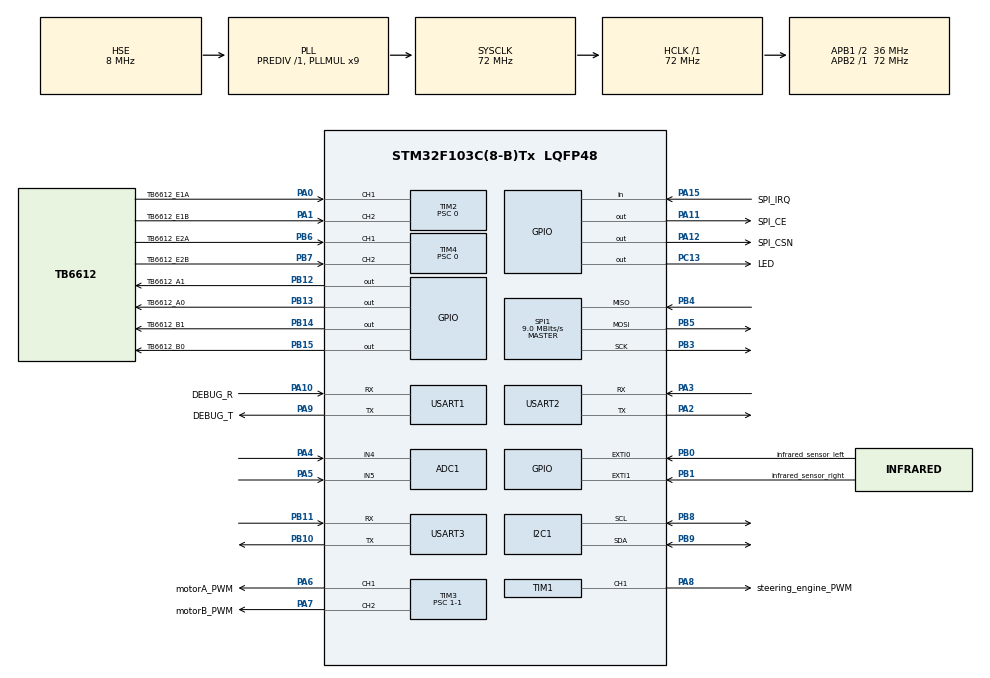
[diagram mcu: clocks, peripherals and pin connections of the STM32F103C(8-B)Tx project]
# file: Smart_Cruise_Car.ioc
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ADC1.Channel-0\#ChannelRegularConversion=ADC_CHANNEL_4
ADC1.NbrOfConversionFlag=1
ADC1.Rank-0\#ChannelRegularConversion=1
ADC1.SamplingTime-0\#ChannelRegularConversion=ADC_SAMPLETIME_1CYCLE_5
ADC1.master=1
Dma.Request0=USART1_RX
Dma.Request1=USART1_TX
Dma.Request2=USART2_RX
Dma.Request3=USART2_TX
Dma.Request4=USART3_RX
Dma.Request5=USART3_TX
Dma.USART1_RX.0.Direction=DMA_PERIPH_TO_MEMORY
Dma.USART1_RX.0.Instance=DMA1_Channel5
Dma.USART1_RX.0.MemDataAlignment=DMA_MDATAALIGN_BYTE
Dma.USART1_RX.0.MemInc=DMA_MINC_ENABLE
Dma.USART1_RX.0.Mode=DMA_NORMAL
Dma.USART1_RX.0.PeriphDataAlignment=DMA_PDATAALIGN_BYTE
Dma.USART1_RX.0.PeriphInc=DMA_PINC_DISABLE
Dma.USART1_RX.0.Priority=DMA_PRIORITY_LOW
Dma.USART1_TX.1.Direction=DMA_MEMORY_TO_PERIPH
Dma.USART1_TX.1.Instance=DMA1_Channel4
Dma.USART1_TX.1.MemDataAlignment=DMA_MDATAALIGN_BYTE
Dma.USART1_TX.1.MemInc=DMA_MINC_ENABLE
Dma.USART1_TX.1.Mode=DMA_NORMAL
Dma.USART1_TX.1.PeriphDataAlignment=DMA_PDATAALIGN_BYTE
Dma.USART1_TX.1.PeriphInc=DMA_PINC_DISABLE
Dma.USART1_TX.1.Priority=DMA_PRIORITY_LOW
Dma.USART2_RX.2.Direction=DMA_PERIPH_TO_MEMORY
Dma.USART2_RX.2.Instance=DMA1_Channel6
Dma.USART2_RX.2.MemDataAlignment=DMA_MDATAALIGN_BYTE
Dma.USART2_RX.2.MemInc=DMA_MINC_ENABLE
Dma.USART2_RX.2.Mode=DMA_NORMAL
Dma.USART2_RX.2.PeriphDataAlignment=DMA_PDATAALIGN_BYTE
Dma.USART2_RX.2.PeriphInc=DMA_PINC_DISABLE
Dma.USART2_RX.2.Priority=DMA_PRIORITY_LOW
Dma.USART2_TX.3.Direction=DMA_MEMORY_TO_PERIPH
Dma.USART2_TX.3.Instance=DMA1_Channel7
Dma.USART2_TX.3.MemDataAlignment=DMA_MDATAALIGN_BYTE
Dma.USART2_TX.3.MemInc=DMA_MINC_ENABLE
Dma.USART2_TX.3.Mode=DMA_NORMAL
Dma.USART2_TX.3.PeriphDataAlignment=DMA_PDATAALIGN_BYTE
Dma.USART2_TX.3.PeriphInc=DMA_PINC_DISABLE
Dma.USART2_TX.3.Priority=DMA_PRIORITY_LOW
Dma.USART3_RX.4.Direction=DMA_PERIPH_TO_MEMORY
Dma.USART3_RX.4.Instance=DMA1_Channel3
Dma.USART3_RX.4.MemDataAlignment=DMA_MDATAALIGN_BYTE
Dma.USART3_RX.4.MemInc=DMA_MINC_ENABLE
Dma.USART3_RX.4.Mode=DMA_NORMAL
Dma.USART3_RX.4.PeriphDataAlignment=DMA_PDATAALIGN_BYTE
Dma.USART3_RX.4.PeriphInc=DMA_PINC_DISABLE
Dma.USART3_RX.4.Priority=DMA_PRIORITY_LOW
Dma.USART3_TX.5.Direction=DMA_MEMORY_TO_PERIPH
Dma.USART3_TX.5.Instance=DMA1_Channel2
Dma.USART3_TX.5.MemDataAlignment=DMA_MDATAALIGN_BYTE
Dma.USART3_TX.5.MemInc=DMA_MINC_ENABLE
Dma.USART3_TX.5.Mode=DMA_NORMAL
Dma.USART3_TX.5.PeriphDataAlignment=DMA_PDATAALIGN_BYTE
Dma.USART3_TX.5.PeriphInc=DMA_PINC_DISABLE
Dma.USART3_TX.5.Priority=DMA_PRIORITY_LOW
FREERTOS.Tasks01=defaultTask,24,128,StartDefaultTask,Default,NULL,Dynamic,NULL,NULL
Mcu.Family=STM32F1
Mcu.Name=STM32F103C(8-B)Tx
Mcu.Package=LQFP48
NVIC.DMA1_Channel2_IRQn=true\:5\:0\:false\:false\:true\:true\:false\:true\:true
NVIC.DMA1_Channel3_IRQn=true\:5\:0\:false\:false\:true\:true\:false\:true\:true
NVIC.DMA1_Channel4_IRQn=true\:5\:0\:false\:false\:true\:true\:false\:true\:true
NVIC.DMA1_Channel5_IRQn=true\:5\:0\:false\:false\:true\:true\:false\:true\:true
NVIC.DMA1_Channel6_IRQn=true\:5\:0\:false\:false\:true\:true\:false\:true\:true
NVIC.DMA1_Channel7_IRQn=true\:5\:0\:false\:false\:true\:true\:false\:true\:true
NVIC.EXTI0_IRQn=true\:5\:0\:false\:false\:true\:true\:true\:true\:true
NVIC.EXTI1_IRQn=true\:5\:0\:false\:false\:true\:true\:true\:true\:true
NVIC.PriorityGroup=NVIC_PRIORITYGROUP_4
PA0-WKUP.GPIO_Label=TB6612_E1A
PA0-WKUP.Signal=S_TIM2_CH1_ETR
PA1.GPIO_Label=TB6612_E1B
PA1.Signal=S_TIM2_CH2
PA10.GPIO_Label=DEBUG_R
PA10.Mode=Asynchronous
PA10.Signal=USART1_RX
PA11.GPIO_Label=SPI_CE
PA11.GPIO_PuPd=GPIO_PULLDOWN
PA11.Signal=GPIO_Output
PA12.GPIO_Label=SPI_CSN
PA12.GPIO_PuPd=GPIO_PULLDOWN
PA12.Signal=GPIO_Output
PA13.Mode=Serial_Wire
PA13.Signal=SYS_JTMS-SWDIO
PA14.Mode=Serial_Wire
PA14.Signal=SYS_JTCK-SWCLK
PA15.GPIO_Label=SPI_IRQ
PA15.GPIO_PuPd=GPIO_PULLDOWN
PA15.Signal=GPIO_Input
PA2.Mode=Asynchronous
PA2.Signal=USART2_TX
PA3.Mode=Asynchronous
PA3.Signal=USART2_RX
PA4.Signal=ADCx_IN4
PA5.Signal=ADCx_IN5
PA6.GPIO_Label=motorA_PWM
PA6.Signal=S_TIM3_CH1
PA7.GPIO_Label=motorB_PWM
PA7.Signal=S_TIM3_CH2
PA8.GPIO_Label=steering_engine_PWM
PA8.Signal=S_TIM1_CH1
PA9.GPIO_Label=DEBUG_T
PA9.Mode=Asynchronous
PA9.Signal=USART1_TX
PB0.GPIO_Label=infrared_sensor_left
PB0.GPIO_ModeDefaultEXTI=GPIO_MODE_IT_RISING_FALLING
PB0.Signal=GPXTI0
PB1.GPIO_Label=infrared_sensor_right
PB1.GPIO_ModeDefaultEXTI=GPIO_MODE_IT_RISING_FALLING
PB1.Signal=GPXTI1
PB10.Mode=Asynchronous
PB10.Signal=USART3_TX
PB11.Mode=Asynchronous
PB11.Signal=USART3_RX
PB12.GPIO_Label=TB6612_A1
PB12.Signal=GPIO_Output
PB13.GPIO_Label=TB6612_A0
PB13.Signal=GPIO_Output
PB14.GPIO_Label=TB6612_B1
PB14.Signal=GPIO_Output
PB15.GPIO_Label=TB6612_B0
PB15.Signal=GPIO_Output
PB3.Mode=Full_Duplex_Master
PB3.Signal=SPI1_SCK
PB4.Mode=Full_Duplex_Master
PB4.Signal=SPI1_MISO
PB5.Mode=Full_Duplex_Master
PB5.Signal=SPI1_MOSI
PB6.GPIO_Label=TB6612_E2A
PB6.Signal=S_TIM4_CH1
PB7.GPIO_Label=TB6612_E2B
PB7.Signal=S_TIM4_CH2
PB8.Mode=I2C
PB8.Signal=I2C1_SCL
PB9.Mode=I2C
PB9.Signal=I2C1_SDA
PC13-TAMPER-RTC.GPIO_Label=LED
PC13-TAMPER-RTC.Signal=GPIO_Output
PD0-OSC_IN.Mode=HSE-External-Oscillator
PD0-OSC_IN.Signal=RCC_OSC_IN
PD1-OSC_OUT.Mode=HSE-External-Oscillator
PD1-OSC_OUT.Signal=RCC_OSC_OUT
ProjectManager.HeapSize=0x200
ProjectManager.StackSize=0x400
ProjectManager.TargetToolchain=MDK-ARM V5.32
RCC.ADCPresc=RCC_ADCPCLK2_DIV6
RCC.AHBFreq_Value=72000000
RCC.APB1CLKDivider=RCC_HCLK_DIV2
RCC.APB1Freq_Value=36000000
RCC.APB1TimFreq_Value=72000000
RCC.APB2Freq_Value=72000000
RCC.APB2TimFreq_Value=72000000
RCC.HCLKFreq_Value=72000000
RCC.PLLMUL=RCC_PLL_MUL9
RCC.PLLSourceVirtual=RCC_PLLSOURCE_HSE
RCC.SYSCLKFreq_VALUE=72000000
RCC.SYSCLKSource=RCC_SYSCLKSOURCE_PLLCLK
RCC.USBFreq_Value=48000000
RCC.USBPrescaler=RCC_USBCLKSOURCE_PLL_DIV1_5
SH.ADCx_IN4.0=ADC1_IN4,IN4
SH.ADCx_IN5.0=ADC1_IN5,IN5
SH.S_TIM1_CH1.0=TIM1_CH1,PWM Generation1 CH1
SH.S_TIM2_CH1_ETR.0=TIM2_CH1,Encoder_Interface
SH.S_TIM2_CH2.0=TIM2_CH2,Encoder_Interface
SH.S_TIM3_CH1.0=TIM3_CH1,PWM Generation1 CH1
SH.S_TIM3_CH2.0=TIM3_CH2,PWM Generation2 CH2
SH.S_TIM4_CH1.0=TIM4_CH1,Encoder_Interface
SH.S_TIM4_CH2.0=TIM4_CH2,Encoder_Interface
SPI1.BaudRatePrescaler=SPI_BAUDRATEPRESCALER_8
SPI1.CRCCalculation=SPI_CRCCALCULATION_DISABLE
SPI1.CalculateBaudRate=9.0 MBits/s
SPI1.Direction=SPI_DIRECTION_2LINES
SPI1.Mode=SPI_MODE_MASTER
SPI1.VirtualType=VM_MASTER
TIM1.Channel-PWM\ Generation1\ CH1=TIM_CHANNEL_1
TIM1.Period=20000-1
TIM1.Prescaler=72-1
TIM2.EncoderMode=TIM_ENCODERMODE_TI12
TIM2.IC1Filter=15
TIM2.IC2Filter=15
TIM2.Prescaler=0
TIM3.Channel-PWM\ Generation1\ CH1=TIM_CHANNEL_1
TIM3.Channel-PWM\ Generation2\ CH2=TIM_CHANNEL_2
TIM3.Period=7200-1
TIM3.Prescaler=1-1
TIM3.Pulse-PWM\ Generation2\ CH2=50
TIM4.EncoderMode=TIM_ENCODERMODE_TI12
TIM4.IC1Filter=15
TIM4.IC2Filter=15
TIM4.Prescaler=0
USART1.VirtualMode=VM_ASYNC
USART2.VirtualMode=VM_ASYNC
USART3.VirtualMode=VM_ASYNC
VP_FREERTOS_VS_CMSIS_V2.Mode=CMSIS_V2
board=custom

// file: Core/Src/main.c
/* USER CODE BEGIN Header */
/**
  ******************************************************************************
  * @file           : main.c
  * @brief          : Main program body
  ******************************************************************************
  * @attention
  *
  * Copyright (c) 2022 STMicroelectronics.
  * All rights reserved.
  *
  * This software is licensed under terms that can be found in the LICENSE file
  * in the root directory of this software component.
  * If no LICENSE file comes with this software, it is provided AS-IS.
  *
  ******************************************************************************
  */
/* USER CODE END Header */
#include "main.h"
#include "cmsis_os.h"
#include "adc.h"
#include "dma.h"
#include "i2c.h"
#include "spi.h"
#include "tim.h"
#include "usart.h"
#include "gpio.h"

void SystemClock_Config(void);
void MX_FREERTOS_Init(void);

int main(void)
{

  /* MCU Configuration--------------------------------------------------------*/

  /* Reset of all peripherals, Initializes the Flash interface and the Systick. */
  HAL_Init();

  /* Configure the system clock */
  SystemClock_Config();

  /* Initialize all configured peripherals */
  MX_GPIO_Init();
  MX_DMA_Init();
  MX_USART1_UART_Init();
  MX_USART2_UART_Init();
  MX_TIM2_Init();
  MX_TIM3_Init();
  MX_USART3_UART_Init();
  MX_SPI1_Init();
  MX_I2C1_Init();
  MX_TIM4_Init();
  MX_TIM1_Init();
  MX_ADC1_Init();

  /* Init scheduler */
  osKernelInitialize();  /* Call init function for freertos objects (in freertos.c) */
  MX_FREERTOS_Init();

  /* Start scheduler */
  osKernelStart();

  /* We should never get here as control is now taken by the scheduler */
  /* Infinite loop */
  while (1)
  {

  }
}

void SystemClock_Config(void)
{
  RCC_OscInitTypeDef RCC_OscInitStruct = {0};
  RCC_ClkInitTypeDef RCC_ClkInitStruct = {0};
  RCC_PeriphCLKInitTypeDef PeriphClkInit = {0};

  /** Initializes the RCC Oscillators according to the specified parameters
  * in the RCC_OscInitTypeDef structure.
  */
  RCC_OscInitStruct.OscillatorType = RCC_OSCILLATORTYPE_HSE;
  RCC_OscInitStruct.HSEState = RCC_HSE_ON;
  RCC_OscInitStruct.HSEPredivValue = RCC_HSE_PREDIV_DIV1;
  RCC_OscInitStruct.HSIState = RCC_HSI_ON;
  RCC_OscInitStruct.PLL.PLLState = RCC_PLL_ON;
  RCC_OscInitStruct.PLL.PLLSource = RCC_PLLSOURCE_HSE;
  RCC_OscInitStruct.PLL.PLLMUL = RCC_PLL_MUL9;
  if (HAL_RCC_OscConfig(&RCC_OscInitStruct) != HAL_OK)
  {
    Error_Handler();
  }

  /** Initializes the CPU, AHB and APB buses clocks
  */
  RCC_ClkInitStruct.ClockType = RCC_CLOCKTYPE_HCLK|RCC_CLOCKTYPE_SYSCLK
                              |RCC_CLOCKTYPE_PCLK1|RCC_CLOCKTYPE_PCLK2;
  RCC_ClkInitStruct.SYSCLKSource = RCC_SYSCLKSOURCE_PLLCLK;
  RCC_ClkInitStruct.AHBCLKDivider = RCC_SYSCLK_DIV1;
  RCC_ClkInitStruct.APB1CLKDivider = RCC_HCLK_DIV2;
  RCC_ClkInitStruct.APB2CLKDivider = RCC_HCLK_DIV1;

  if (HAL_RCC_ClockConfig(&RCC_ClkInitStruct, FLASH_LATENCY_2) != HAL_OK)
  {
    Error_Handler();
  }
  PeriphClkInit.PeriphClockSelection = RCC_PERIPHCLK_ADC;
  PeriphClkInit.AdcClockSelection = RCC_ADCPCLK2_DIV6;
  if (HAL_RCCEx_PeriphCLKConfig(&PeriphClkInit) != HAL_OK)
  {
    Error_Handler();
  }
}

void Error_Handler(void)
{
  __disable_irq();
  while (1)
  {
  }
}

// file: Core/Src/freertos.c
/* USER CODE BEGIN Header */
/**
  ******************************************************************************
  * File Name          : freertos.c
  * Description        : Code for freertos applications
  ******************************************************************************
  * @attention
  *
  * Copyright (c) 2022 STMicroelectronics.
  * All rights reserved.
  *
  * This software is licensed under terms that can be found in the LICENSE file
  * in the root directory of this software component.
  * If no LICENSE file comes with this software, it is provided AS-IS.
  *
  ******************************************************************************
  */
/* USER CODE END Header */

#include "FreeRTOS.h"
#include "task.h"
#include "main.h"
#include "cmsis_os.h"

/* USER CODE BEGIN Includes */
#include "App_Main.h"
/* USER CODE END Includes */

/* Definitions for defaultTask */
osThreadId_t defaultTaskHandle;
const osThreadAttr_t defaultTask_attributes = {
  .name = "defaultTask",
  .stack_size = 128 * 4,
  .priority = (osPriority_t) osPriorityNormal,
};

void StartDefaultTask(void *argument);

void MX_FREERTOS_Init(void); /* (MISRA C 2004 rule 8.1) */

void MX_FREERTOS_Init(void) {

  /* Create the thread(s) */
  /* creation of defaultTask */
  defaultTaskHandle = osThreadNew(StartDefaultTask, NULL, &defaultTask_attributes);

}

void StartDefaultTask(void *argument)
{
  /* USER CODE BEGIN StartDefaultTask */
	 APP_Main();
  /* Infinite loop */
  for(;;)
  {
    osDelay(1);
  }
  /* USER CODE END StartDefaultTask */
}
